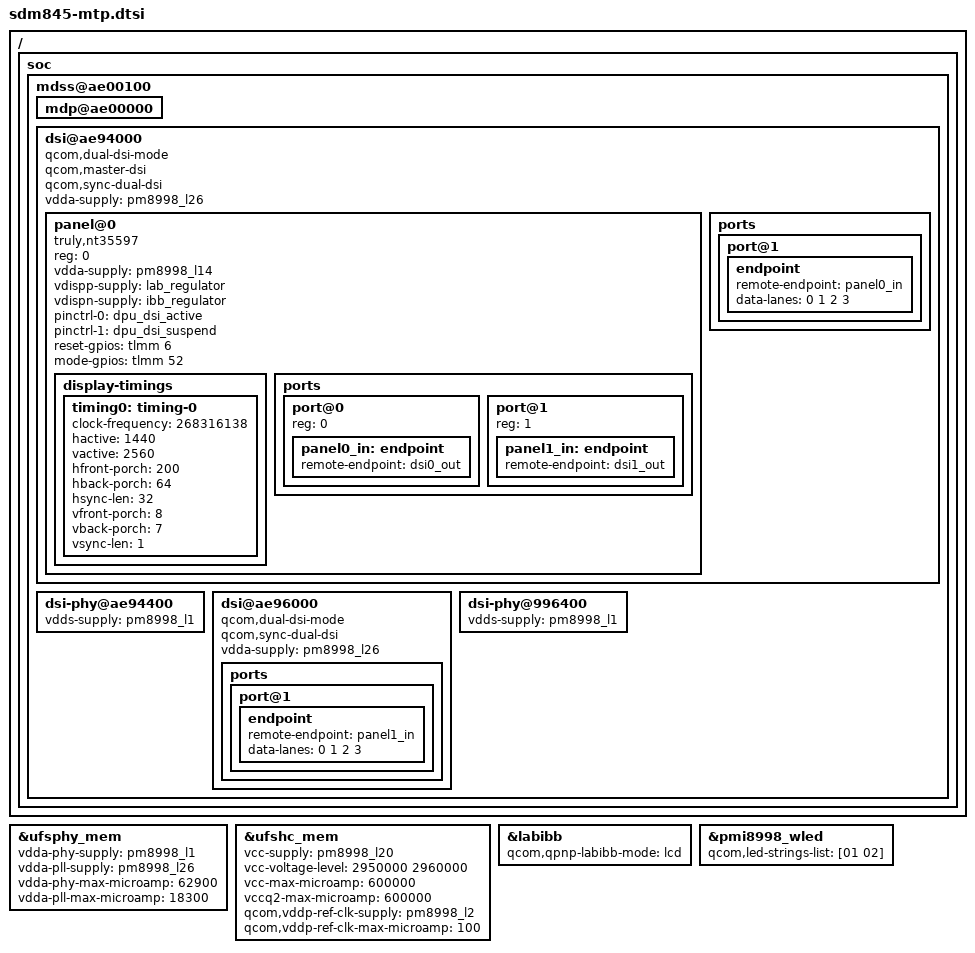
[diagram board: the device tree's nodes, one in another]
/* Copyright (c) 2016-2018, The Linux Foundation. All rights reserved.
 *
 * This program is free software; you can redistribute it and/or modify
 * it under the terms of the GNU General Public License version 2 and
 * only version 2 as published by the Free Software Foundation.
 *
 * This program is distributed in the hope that it will be useful,
 * but WITHOUT ANY WARRANTY; without even the implied warranty of
 * MERCHANTABILITY or FITNESS FOR A PARTICULAR PURPOSE.  See the
 * GNU General Public License for more details.
 */

#include <dt-bindings/gpio/gpio.h>
#include "sdm845.dtsi"

/ {
	soc {
		mdss@ae00100 {
			status = "ok";

			mdp@ae00000 {
				status = "ok";
			};

			dsi@ae94000 {
				status = "ok";
				qcom,dual-dsi-mode;
				qcom,master-dsi;
				qcom,sync-dual-dsi;

				vdda-supply = <&pm8998_l26>;

				panel@0 {
					compatible = "truly,nt35597";
					reg = <0>;

					vdda-supply = <&pm8998_l14>;
					vdispp-supply = <&lab_regulator>;
					vdispn-supply = <&ibb_regulator>;

					pinctrl-names = "default", "suspend";
					pinctrl-0 = <&dpu_dsi_active>;
					pinctrl-1 = <&dpu_dsi_suspend>;

					reset-gpios = <&tlmm 6 0>;
					mode-gpios = <&tlmm 52 0>;

					display-timings {
						timing0: timing-0 {
							/* originally
							 * 268316160 Mhz,
							 * but value below fits
							 * better w/ downstream
							 */
							clock-frequency = <268316138>;
							hactive = <1440>;
							vactive = <2560>;
							hfront-porch = <200>;
							hback-porch = <64>;
							hsync-len = <32>;
							vfront-porch = <8>;
							vback-porch = <7>;
							vsync-len = <1>;
						};
					};
					ports {
						#address-cells = <1>;
						#size-cells = <0>;
						port@0 {
							reg = <0>;
							panel0_in: endpoint {
								remote-endpoint = <&dsi0_out>;
							};
						};

						port@1 {
							reg = <1>;
							panel1_in: endpoint {
								remote-endpoint = <&dsi1_out>;
							};
						};
					};
				};

				ports {
					port@1 {
						endpoint {
							remote-endpoint = <&panel0_in>;
							data-lanes = <0 1 2 3>;
						};
					};
				};
			};

			dsi-phy@ae94400 {
				status = "okay";

				vdds-supply = <&pm8998_l1>;
			};

			dsi@ae96000 {
				status = "okay";

				qcom,dual-dsi-mode;
				qcom,sync-dual-dsi;

				vdda-supply = <&pm8998_l26>;

				ports {
					port@1 {
						endpoint {
							remote-endpoint = <&panel1_in>;
							data-lanes = <0 1 2 3>;
						};
					};
				};
			};

			dsi-phy@996400 {
				status = "okay";

				vdds-supply = <&pm8998_l1>;
			};
		};
	};
};

&ufsphy_mem {
	vdda-phy-supply = <&pm8998_l1>; /* 0.88v */
	vdda-pll-supply = <&pm8998_l26>; /* 1.2v */
	vdda-phy-max-microamp = <62900>;
	vdda-pll-max-microamp = <18300>;

	status = "ok";
};

&ufshc_mem {
	vcc-supply = <&pm8998_l20>;
	vcc-voltage-level = <2950000 2960000>;
	vcc-max-microamp = <600000>;
	vccq2-max-microamp = <600000>;

	qcom,vddp-ref-clk-supply = <&pm8998_l2>;
	qcom,vddp-ref-clk-max-microamp = <100>;

	status = "ok";
};

&labibb {
	status = "ok";
	qcom,qpnp-labibb-mode = "lcd";
};

&pmi8998_wled {
	status = "okay";
	qcom,led-strings-list = [01 02];
};
